AUTOSAR XML (schema 4-2-2)
package /AUTOLIV/SoftwareComponents/DemIf
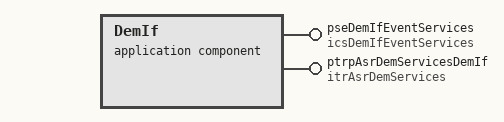
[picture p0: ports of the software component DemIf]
  application sw component type DemIf: category=BSW_System_Services
    provide port pseDemIfEventServices: server-com-spec{operation=GetCounterPassedThreshold, queue-length=1}, provided-interface=icsDemIfEventServices  # # Architecture Element ID ARCH_SW_Dem_GetEventDebounceTime # Description - Interface is used to read the counter value which should be reached in order to set the event as PASSED; - Interface will provide the {Event_ID} as input and will retrieve the {Counter_Value} of the corresponding event; # Data Flow ## Inputs: - {Event_ID}: The ID of event; ## Outputs: - {Counter_Value}: value of the Pass confirmation counter; # Linked Runnable - Dem_GetEventDebounceTime # Traceability
    provide port ptrpAsrDemServicesDemIf: provided-interface=itrAsrDemServices  # # Architecture Element ID ARCH_SW_DemIf_ptrpAsrDemServices # Description - The callback shall be called by Dem in order to signal the fact that an event status has changed - The runnable shall report the {New Event Status} and {Old Event Status} for the Dem {Event Id} # Data Flow ## Inputs - {Event Id} - {Old Event Status} - {New Event Status} # Linked Runnable - Dem_Callback_EventStatusChanged #Traceability
